AUTOSAR XML (schema 4-0-3)
package /CalibrationComponents
  parameter sw component type DHSR: data-type-mapping=DHSR_CodeDataTypeMappingsSet
    provide port DHSR_Pport: provided-interface=DHSR_if
      provided-com-specs:
        init-value=3, parameter=KeDHSR_kmh_VehSpeedProgAlwd
        init-value=0, parameter=KeDHSR_r_ChrgFactor_Val
        init-value=0, parameter=KeDHSR_r_RegenFactor_Val
        init-value=0, parameter=KeDHSR_r_SOPFactor_Val
        init-value=2, parameter=KeDHSR_t_BPOdbnc1
        init-value=5, parameter=KeDHSR_t_BPOdbnc2
        init-value=8, parameter=KeDHSR_t_BPOdbnc3
        init-value=30, parameter=KeDHSR_t_BPOdbnc4
        init-value=0, parameter=KeDHSR_b_BattPowerOff_En
        init-value=1, parameter=KeDHSR_b_BattPowerOff_Val
        init-value=0, parameter=KeDHSR_b_ChrgFactor_En
        init-value=0, parameter=KeDHSR_b_Discharge10Kw_En
        init-value=0, parameter=KeDHSR_b_Discharge10Kw_Val
        init-value=0, parameter=KeDHSR_b_FaultLamp_En
        init-value=0, parameter=KeDHSR_b_FaultLamp_Val
        init-value=0, parameter=KeDHSR_b_NoCellBalance_En
        init-value=0, parameter=KeDHSR_b_NoCellBalance_Val
        init-value=0, parameter=KeDHSR_b_NoHeat_En
        init-value=0, parameter=KeDHSR_b_NoHeat_Val
        init-value=0, parameter=KeDHSR_b_NoPrecharge_En
        init-value=0, parameter=KeDHSR_b_NoPrecharge_Val
        init-value=0, parameter=KeDHSR_b_RegenFactor_En
        init-value=0, parameter=KeDHSR_b_ReqPowerOff_En
        init-value=0, parameter=KeDHSR_b_ReqPowerOff_Val
        init-value=0, parameter=KeDHSR_b_SOCTo0_En
        init-value=0, parameter=KeDHSR_b_SOPFactor_En
        init-value=0, parameter=KeDHSR_b_SOCTo0_Val
package /DHSR_Code_pkg/DHSR_Code_swc
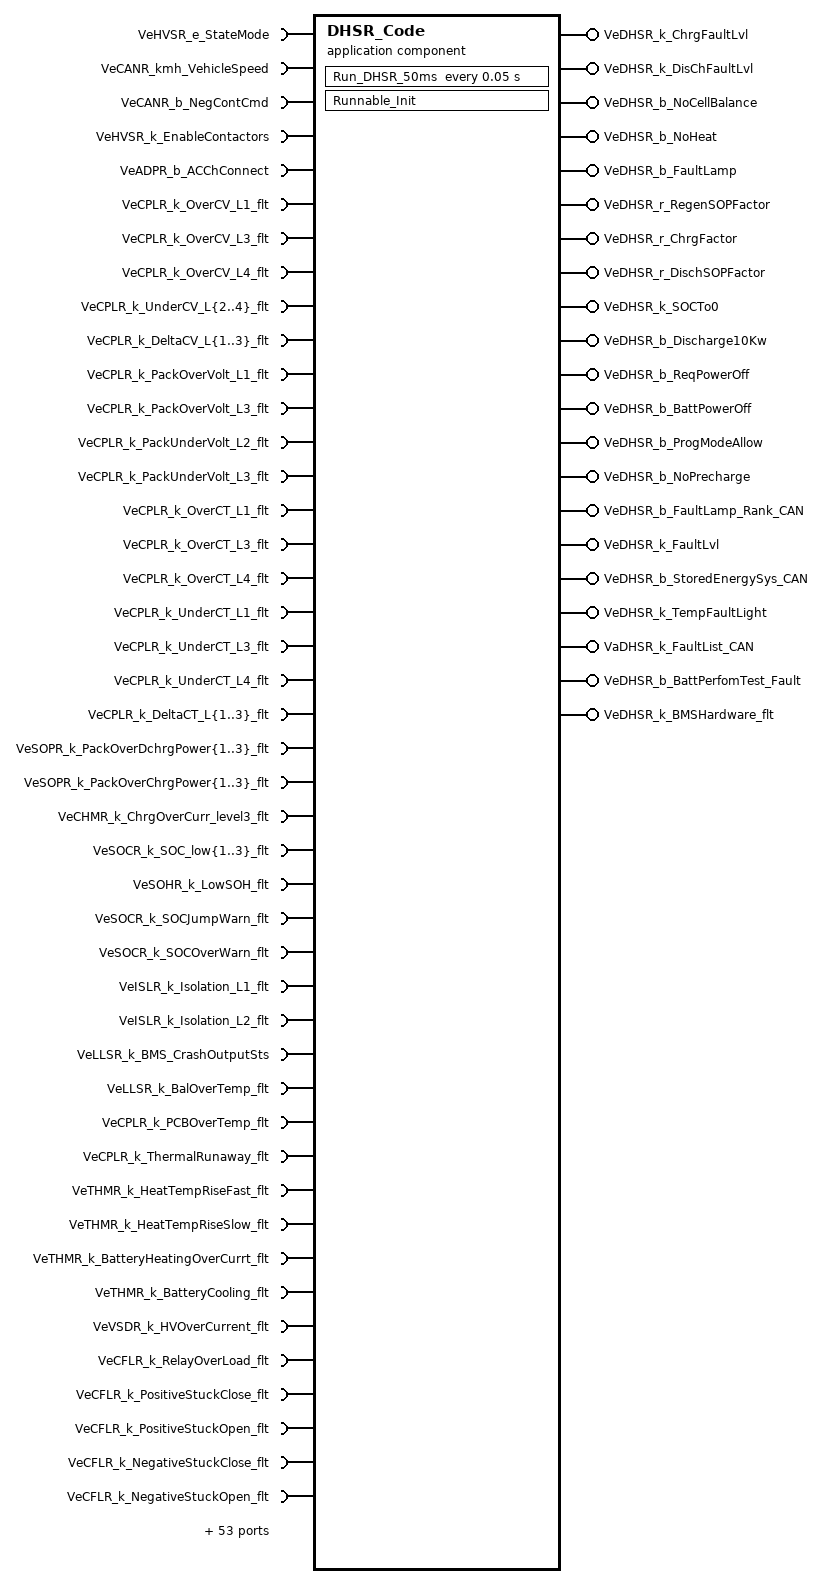
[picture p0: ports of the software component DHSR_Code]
  application sw component type DHSR_Code
    108 x require port:
      VeHVSR_e_StateMode: nonqueued-receiver-com-spec{data-element=VeHVSR_e_StateMode, init-value=CeHVSR_e_StateModeReserved}, required-interface=VeHVSR_e_StateMode
      VeCANR_kmh_VehicleSpeed: nonqueued-receiver-com-spec{data-element=VeCANR_kmh_VehicleSpeed, init-value=0}, required-interface=VeCANR_kmh_VehicleSpeed
      VeCANR_b_NegContCmd: nonqueued-receiver-com-spec{data-element=VeCANR_b_NegContCmd, init-value=0}, required-interface=VeCANR_b_NegContCmd
      VeHVSR_k_EnableContactors: nonqueued-receiver-com-spec{data-element=VeHVSR_k_EnableContactors, init-value=0}, required-interface=VeHVSR_k_EnableContactors
      VeADPR_b_ACChConnect: nonqueued-receiver-com-spec{data-element=VeADPR_b_ACChConnect, init-value=0}, required-interface=VeADPR_b_ACChConnect
      VeCPLR_k_OverCV_L1_flt: nonqueued-receiver-com-spec{data-element=VeCPLR_k_OverCV_L1_flt, init-value=0}, required-interface=VeCPLR_k_OverCV_L1_flt
      VeCPLR_k_OverCV_L3_flt: nonqueued-receiver-com-spec{data-element=VeCPLR_k_OverCV_L3_flt, init-value=0}, required-interface=VeCPLR_k_OverCV_L3_flt
      VeCPLR_k_OverCV_L4_flt: nonqueued-receiver-com-spec{data-element=VeCPLR_k_OverCV_L4_flt, init-value=0}, required-interface=VeCPLR_k_OverCV_L4_flt
      VeCPLR_k_UnderCV_L{2..4}_flt: nonqueued-receiver-com-spec{data-element=VeCPLR_k_UnderCV_L{2..4}_flt, init-value=0}, required-interface=VeCPLR_k_UnderCV_L{2..4}_flt
      VeCPLR_k_DeltaCV_L{1..3}_flt: nonqueued-receiver-com-spec{data-element=VeCPLR_k_DeltaCV_L{1..3}_flt, init-value=0}, required-interface=VeCPLR_k_DeltaCV_L{1..3}_flt
      VeCPLR_k_PackOverVolt_L1_flt: nonqueued-receiver-com-spec{data-element=VeCPLR_k_PackOverVolt_L1_flt, init-value=0}, required-interface=VeCPLR_k_PackOverVolt_L1_flt
      VeCPLR_k_PackOverVolt_L3_flt: nonqueued-receiver-com-spec{data-element=VeCPLR_k_PackOverVolt_L3_flt, init-value=0}, required-interface=VeCPLR_k_PackOverVolt_L3_flt
      VeCPLR_k_PackUnderVolt_L2_flt: nonqueued-receiver-com-spec{data-element=VeCPLR_k_PackUnderVolt_L2_flt, init-value=0}, required-interface=VeCPLR_k_PackUnderVolt_L2_flt
      VeCPLR_k_PackUnderVolt_L3_flt: nonqueued-receiver-com-spec{data-element=VeCPLR_k_PackUnderVolt_L3_flt, init-value=0}, required-interface=VeCPLR_k_PackUnderVolt_L3_flt
      VeCPLR_k_OverCT_L1_flt: nonqueued-receiver-com-spec{data-element=VeCPLR_k_OverCT_L1_flt, init-value=0}, required-interface=VeCPLR_k_OverCT_L1_flt
      VeCPLR_k_OverCT_L3_flt: nonqueued-receiver-com-spec{data-element=VeCPLR_k_OverCT_L3_flt, init-value=0}, required-interface=VeCPLR_k_OverCT_L3_flt
      VeCPLR_k_OverCT_L4_flt: nonqueued-receiver-com-spec{data-element=VeCPLR_k_OverCT_L4_flt, init-value=0}, required-interface=VeCPLR_k_OverCT_L4_flt
      VeCPLR_k_UnderCT_L1_flt: nonqueued-receiver-com-spec{data-element=VeCPLR_k_UnderCT_L1_flt, init-value=0}, required-interface=VeCPLR_k_UnderCT_L1_flt
      VeCPLR_k_UnderCT_L3_flt: nonqueued-receiver-com-spec{data-element=VeCPLR_k_UnderCT_L3_flt, init-value=0}, required-interface=VeCPLR_k_UnderCT_L3_flt
      VeCPLR_k_UnderCT_L4_flt: nonqueued-receiver-com-spec{data-element=VeCPLR_k_UnderCT_L4_flt, init-value=0}, required-interface=VeCPLR_k_UnderCT_L4_flt
      VeCPLR_k_DeltaCT_L{1..3}_flt: nonqueued-receiver-com-spec{data-element=VeCPLR_k_DeltaCT_L{1..3}_flt, init-value=0}, required-interface=VeCPLR_k_DeltaCT_L{1..3}_flt
      VeSOPR_k_PackOverDchrgPower{1..3}_flt: nonqueued-receiver-com-spec{data-element=VeSOPR_k_PackOverDchrgPower{1..3}_flt, init-value=0}, required-interface=VeSOPR_k_PackOverDchrgPower{1..3}_flt
      VeSOPR_k_PackOverChrgPower{1..3}_flt: nonqueued-receiver-com-spec{data-element=VeSOPR_k_PackOverChrgPower{1..3}_flt, init-value=0}, required-interface=VeSOPR_k_PackOverChrgPower{1..3}_flt
      VeCHMR_k_ChrgOverCurr_level3_flt: nonqueued-receiver-com-spec{data-element=VeCHMR_k_ChrgOverCurr_level3_flt, init-value=0}, required-interface=VeCHMR_k_ChrgOverCurr_level3_flt
      VeSOCR_k_SOC_low{1..3}_flt: nonqueued-receiver-com-spec{data-element=VeSOCR_k_SOC_low{1..3}_flt, init-value=0}, required-interface=VeSOCR_k_SOC_low{1..3}_flt
      VeSOHR_k_LowSOH_flt: nonqueued-receiver-com-spec{data-element=VeSOHR_k_LowSOH_flt, init-value=0}, required-interface=VeSOHR_k_LowSOH_flt
      VeSOCR_k_SOCJumpWarn_flt: nonqueued-receiver-com-spec{data-element=VeSOCR_k_SOCJumpWarn_flt, init-value=0}, required-interface=VeSOCR_k_SOCJumpWarn_flt
      VeSOCR_k_SOCOverWarn_flt: nonqueued-receiver-com-spec{data-element=VeSOCR_k_SOCOverWarn_flt, init-value=0}, required-interface=VeSOCR_k_SOCOverWarn_flt
      VeISLR_k_Isolation_L1_flt: nonqueued-receiver-com-spec{data-element=VeISLR_k_Isolation_L1_flt, init-value=0}, required-interface=VeISLR_k_Isolation_L1_flt
      VeISLR_k_Isolation_L2_flt: nonqueued-receiver-com-spec{data-element=VeISLR_k_Isolation_L2_flt, init-value=0}, required-interface=VeISLR_k_Isolation_L2_flt
      VeLLSR_k_BMS_CrashOutputSts: nonqueued-receiver-com-spec{data-element=VeLLSR_k_BMS_CrashOutputSts, init-value=0}, required-interface=VeLLSR_k_BMS_CrashOutputSts
      VeLLSR_k_BalOverTemp_flt: nonqueued-receiver-com-spec{data-element=VeLLSR_k_BalOverTemp_flt, init-value=0}, required-interface=VeLLSR_k_BalOverTemp_flt
      VeCPLR_k_PCBOverTemp_flt: nonqueued-receiver-com-spec{data-element=VeCPLR_k_PCBOverTemp_flt, init-value=0}, required-interface=VeCPLR_k_PCBOverTemp_flt
      VeCPLR_k_ThermalRunaway_flt: nonqueued-receiver-com-spec{data-element=VeCPLR_k_ThermalRunaway_flt, init-value=0}, required-interface=VeCPLR_k_ThermalRunaway_flt
      VeTHMR_k_HeatTempRiseFast_flt: nonqueued-receiver-com-spec{data-element=VeTHMR_k_HeatTempRiseFast_flt, init-value=0}, required-interface=VeTHMR_k_HeatTempRiseFast_flt
      VeTHMR_k_HeatTempRiseSlow_flt: nonqueued-receiver-com-spec{data-element=VeTHMR_k_HeatTempRiseSlow_flt, init-value=0}, required-interface=VeTHMR_k_HeatTempRiseSlow_flt
      VeTHMR_k_BatteryHeatingOverCurrt_flt: nonqueued-receiver-com-spec{data-element=VeTHMR_k_BatteryHeatingOverCurrt_flt, init-value=0}, required-interface=VeTHMR_k_BatteryHeatingOverCurrt_flt
      VeTHMR_k_BatteryCooling_flt: nonqueued-receiver-com-spec{data-element=VeTHMR_k_BatteryCooling_flt, init-value=0}, required-interface=VeTHMR_k_BatteryCooling_flt
      VeVSDR_k_HVOverCurrent_flt: nonqueued-receiver-com-spec{data-element=VeVSDR_k_HVOverCurrent_flt, init-value=0}, required-interface=VeVSDR_k_HVOverCurrent_flt
      VeCFLR_k_RelayOverLoad_flt: nonqueued-receiver-com-spec{data-element=VeCFLR_k_RelayOverLoad_flt, init-value=0}, required-interface=VeCFLR_k_RelayOverLoad_flt
      VeCFLR_k_PositiveStuckClose_flt: nonqueued-receiver-com-spec{data-element=VeCFLR_k_PositiveStuckClose_flt, init-value=0}, required-interface=VeCFLR_k_PositiveStuckClose_flt
      VeCFLR_k_PositiveStuckOpen_flt: nonqueued-receiver-com-spec{data-element=VeCFLR_k_PositiveStuckOpen_flt, init-value=0}, required-interface=VeCFLR_k_PositiveStuckOpen_flt
      VeCFLR_k_NegativeStuckClose_flt: nonqueued-receiver-com-spec{data-element=VeCFLR_k_NegativeStuckClose_flt, init-value=0}, required-interface=VeCFLR_k_NegativeStuckClose_flt
      VeCFLR_k_NegativeStuckOpen_flt: nonqueued-receiver-com-spec{data-element=VeCFLR_k_NegativeStuckOpen_flt, init-value=0}, required-interface=VeCFLR_k_NegativeStuckOpen_flt
      VeCFLR_k_PrechargeStuckClose_flt: nonqueued-receiver-com-spec{data-element=VeCFLR_k_PrechargeStuckClose_flt, init-value=0}, required-interface=VeCFLR_k_PrechargeStuckClose_flt
      VeCFLR_k_PrechargeStuckOpen_flt: nonqueued-receiver-com-spec{data-element=VeCFLR_k_PrechargeStuckOpen_flt, init-value=0}, required-interface=VeCFLR_k_PrechargeStuckOpen_flt
      VeCFLR_k_MainFuse1Open_flt: nonqueued-receiver-com-spec{data-element=VeCFLR_k_MainFuse1Open_flt, init-value=0}, required-interface=VeCFLR_k_MainFuse1Open_flt
      VeCFLR_k_MainFuse2Open_flt: nonqueued-receiver-com-spec{data-element=VeCFLR_k_MainFuse2Open_flt, init-value=0}, required-interface=VeCFLR_k_MainFuse2Open_flt
      VeHVIR_k_MainHVIL2_flt: nonqueued-receiver-com-spec{data-element=VeHVIR_k_MainHVIL2_flt, init-value=0}, required-interface=VeHVIR_k_MainHVIL2_flt
      VeHVIR_k_MainHVIL_flt: nonqueued-receiver-com-spec{data-element=VeHVIR_k_MainHVIL_flt, init-value=0}, required-interface=VeHVIR_k_MainHVIL_flt
      VeISLR_InterIsolation_flt: nonqueued-receiver-com-spec{data-element=VeISLR_InterIsolation_flt, init-value=0}, required-interface=VeISLR_InterIsolation_flt
      VeISLR_ExterIsolation_flt: nonqueued-receiver-com-spec{data-element=VeISLR_ExterIsolation_flt, init-value=0}, required-interface=VeISLR_ExterIsolation_flt
      VeCFLR_k_PreResistorStuckOpen_flt: nonqueued-receiver-com-spec{data-element=VeCFLR_k_PreResistorStuckOpen_flt, init-value=0}, required-interface=VeCFLR_k_PreResistorStuckOpen_flt
      VeCFLR_k_PreChargeFail_flt: nonqueued-receiver-com-spec{data-element=VeCFLR_k_PreChargeFail_flt, init-value=0}, required-interface=VeCFLR_k_PreChargeFail_flt
      VeCFLR_k_PreChargeOvCur_flt: nonqueued-receiver-com-spec{data-element=VeCFLR_k_PreChargeOvCur_flt, init-value=0}, required-interface=VeCFLR_k_PreChargeOvCur_flt
      VeCFLR_k_PassiveMcuDischarge_flt: nonqueued-receiver-com-spec{data-element=VeCFLR_k_PassiveMcuDischarge_flt, init-value=0}, required-interface=VeCFLR_k_PassiveMcuDischarge_flt
      VeCFLR_k_ConDrvPosCircuit_flt: nonqueued-receiver-com-spec{data-element=VeCFLR_k_ConDrvPosCircuit_flt, init-value=0}, required-interface=VeCFLR_k_ConDrvPosCircuit_flt
      VeCFLR_k_ConDrvNegCircuit_flt: nonqueued-receiver-com-spec{data-element=VeCFLR_k_ConDrvNegCircuit_flt, init-value=0}, required-interface=VeCFLR_k_ConDrvNegCircuit_flt
      VeCFLR_k_ConDrvPreCircuit_flt: nonqueued-receiver-com-spec{data-element=VeCFLR_k_ConDrvPreCircuit_flt, init-value=0}, required-interface=VeCFLR_k_ConDrvPreCircuit_flt
      VeVSDR_k_LinkVoltageInRange_flt: nonqueued-receiver-com-spec{data-element=VeVSDR_k_LinkVoltageInRange_flt, init-value=0}, required-interface=VeVSDR_k_LinkVoltageInRange_flt
      VeVSDR_k_PackVoltageInRange_flt: nonqueued-receiver-com-spec{data-element=VeVSDR_k_PackVoltageInRange_flt, init-value=0}, required-interface=VeVSDR_k_PackVoltageInRange_flt
      VeVSDR_k_VoltMCUFInRange_flt: nonqueued-receiver-com-spec{data-element=VeVSDR_k_VoltMCUFInRange_flt, init-value=0}, required-interface=VeVSDR_k_VoltMCUFInRange_flt
      VeVSDR_k_VoltMCURInRange_flt: nonqueued-receiver-com-spec{data-element=VeVSDR_k_VoltMCURInRange_flt, init-value=0}, required-interface=VeVSDR_k_VoltMCURInRange_flt
      VeCSCR_k_CellCircuit_flt: nonqueued-receiver-com-spec{data-element=VeCSCR_k_CellCircuit_flt, init-value=0}, required-interface=VeCSCR_k_CellCircuit_flt
      VeCSCR_k_StackCircuit_flt: nonqueued-receiver-com-spec{data-element=VeCSCR_k_StackCircuit_flt, init-value=0}, required-interface=VeCSCR_k_StackCircuit_flt
      VeCSCR_k_TempArray_flt: nonqueued-receiver-com-spec{data-element=VeCSCR_k_TempArray_flt, init-value=0}, required-interface=VeCSCR_k_TempArray_flt
      VeCSCR_k_PackVolt_flt: nonqueued-receiver-com-spec{data-element=VeCSCR_k_PackVolt_flt, init-value=0}, required-interface=VeCSCR_k_PackVolt_flt
      VeCSCR_k_LinkPVolt_flt: nonqueued-receiver-com-spec{data-element=VeCSCR_k_LinkPVolt_flt, init-value=0}, required-interface=VeCSCR_k_LinkPVolt_flt
      VeCSCR_k_HeatVolt_flt: nonqueued-receiver-com-spec{data-element=VeCSCR_k_HeatVolt_flt, init-value=0}, required-interface=VeCSCR_k_HeatVolt_flt
      VeCSCR_k_LinkNVolt_flt: nonqueued-receiver-com-spec{data-element=VeCSCR_k_LinkNVolt_flt, init-value=0}, required-interface=VeCSCR_k_LinkNVolt_flt
      VeLLSR_k_CrashCircuit_flt: nonqueued-receiver-com-spec{data-element=VeLLSR_k_CrashCircuit_flt, init-value=0}, required-interface=VeLLSR_k_CrashCircuit_flt
      VeLLSR_k_PackCrntCircuit_flt: nonqueued-receiver-com-spec{data-element=VeLLSR_k_PackCrntCircuit_flt, init-value=0}, required-interface=VeLLSR_k_PackCrntCircuit_flt
      VeCSCR_k_CBCircuit_flt: nonqueued-receiver-com-spec{data-element=VeCSCR_k_CBCircuit_flt, init-value=0}, required-interface=VeCSCR_k_CBCircuit_flt
      VeCSCR_k_PCBTempInv_Flt: nonqueued-receiver-com-spec{data-element=VeCSCR_k_PCBTempInv_Flt, init-value=0}, required-interface=VeCSCR_k_PCBTempInv_Flt
      VeHVIR_k_MainHVILCircuit_flt: nonqueued-receiver-com-spec{data-element=VeHVIR_k_MainHVILCircuit_flt, init-value=0}, required-interface=VeHVIR_k_MainHVILCircuit_flt
      VeHVIR_k_MainHVILCircuit2_flt: nonqueued-receiver-com-spec{data-element=VeHVIR_k_MainHVILCircuit2_flt, init-value=0}, required-interface=VeHVIR_k_MainHVILCircuit2_flt
      VeLLSR_k_ExtEEP_flt: nonqueued-receiver-com-spec{data-element=VeLLSR_k_ExtEEP_flt, init-value=0}, required-interface=VeLLSR_k_ExtEEP_flt
      VeLLSR_k_DaisyCom_flt: nonqueued-receiver-com-spec{data-element=VeLLSR_k_DaisyCom_flt, init-value=0}, required-interface=VeLLSR_k_DaisyCom_flt
      VeLLSR_k_VCUComLoss_flt: nonqueued-receiver-com-spec{data-element=VeLLSR_k_VCUComLoss_flt, init-value=0}, required-interface=VeLLSR_k_VCUComLoss_flt
      VeLLSR_k_OBCComLoss_flt: nonqueued-receiver-com-spec{data-element=VeLLSR_k_OBCComLoss_flt, init-value=0}, required-interface=VeLLSR_k_OBCComLoss_flt
      VeLLSR_k_TMFComLoss_flt: nonqueued-receiver-com-spec{data-element=VeLLSR_k_TMFComLoss_flt, init-value=0}, required-interface=VeLLSR_k_TMFComLoss_flt
      VeLLSR_k_TMRComLoss_flt: nonqueued-receiver-com-spec{data-element=VeLLSR_k_TMRComLoss_flt, init-value=0}, required-interface=VeLLSR_k_TMRComLoss_flt
      VeLLSR_k_ISGFComLoss_flt: nonqueued-receiver-com-spec{data-element=VeLLSR_k_ISGFComLoss_flt, init-value=0}, required-interface=VeLLSR_k_ISGFComLoss_flt
      VeLLSR_k_CDUComLoss_flt: nonqueued-receiver-com-spec{data-element=VeLLSR_k_CDUComLoss_flt, init-value=0}, required-interface=VeLLSR_k_CDUComLoss_flt
      VeLLSR_k_CLMComLoss_flt: nonqueued-receiver-com-spec{data-element=VeLLSR_k_CLMComLoss_flt, init-value=0}, required-interface=VeLLSR_k_CLMComLoss_flt
      VeLLSR_k_ABMComLoss_flt: nonqueued-receiver-com-spec{data-element=VeLLSR_k_ABMComLoss_flt, init-value=0}, required-interface=VeLLSR_k_ABMComLoss_flt
      VeLLSR_k_ICMComLoss_flt: nonqueued-receiver-com-spec{data-element=VeLLSR_k_ICMComLoss_flt, init-value=0}, required-interface=VeLLSR_k_ICMComLoss_flt
      VeLLSR_k_TBOXComLoss_flt: nonqueued-receiver-com-spec{data-element=VeLLSR_k_TBOXComLoss_flt, init-value=0}, required-interface=VeLLSR_k_TBOXComLoss_flt
      VeLLSR_k_BSMComLoss_flt: nonqueued-receiver-com-spec{data-element=VeLLSR_k_BSMComLoss_flt, init-value=0}, required-interface=VeLLSR_k_BSMComLoss_flt
      VeLLSR_k_EMSComLoss_flt: nonqueued-receiver-com-spec{data-element=VeLLSR_k_EMSComLoss_flt, init-value=0}, required-interface=VeLLSR_k_EMSComLoss_flt
      VeLLSR_k_VehCANBusOff_flt: nonqueued-receiver-com-spec{data-element=VeLLSR_k_VehCANBusOff_flt, init-value=0}, required-interface=VeLLSR_k_VehCANBusOff_flt
      VeLLSR_k_KL30UnderVoltage_flt: nonqueued-receiver-com-spec{data-element=VeLLSR_k_KL30UnderVoltage_flt, init-value=0}, required-interface=VeLLSR_k_KL30UnderVoltage_flt
      VeLLSR_k_KL30OverVoltage_flt: nonqueued-receiver-com-spec{data-element=VeLLSR_k_KL30OverVoltage_flt, init-value=0}, required-interface=VeLLSR_k_KL30OverVoltage_flt
      VeLLSR_k_KL30AccidentalPowerOff_flt: nonqueued-receiver-com-spec{data-element=VeLLSR_k_KL30AccidentalPowerOff_flt, init-value=0}, required-interface=VeLLSR_k_KL30AccidentalPowerOff_flt
      VeCFLR_k_UnexpectedContOpen_flt: nonqueued-receiver-com-spec{data-element=VeCFLR_k_UnexpectedContOpen_flt, init-value=0}, required-interface=VeCFLR_k_UnexpectedContOpen_flt
      VeLLSR_k_AbnormalShutdownDetected: nonqueued-receiver-com-spec{data-element=VeLLSR_k_AbnormalShutdownDetected, init-value=0}, required-interface=VeLLSR_k_AbnormalShutdownDetected
    21 x provide port:
      VeDHSR_k_ChrgFaultLvl: nonqueued-sender-com-spec{data-element=VeDHSR_k_ChrgFaultLvl, init-value=0}, provided-interface=VeDHSR_k_ChrgFaultLvl
      VeDHSR_k_DisChFaultLvl: nonqueued-sender-com-spec{data-element=VeDHSR_k_DisChFaultLvl, init-value=0}, provided-interface=VeDHSR_k_DisChFaultLvl
      VeDHSR_b_NoCellBalance: nonqueued-sender-com-spec{data-element=VeDHSR_b_NoCellBalance, init-value=0}, provided-interface=VeDHSR_b_NoCellBalance
      VeDHSR_b_NoHeat: nonqueued-sender-com-spec{data-element=VeDHSR_b_NoHeat, init-value=0}, provided-interface=VeDHSR_b_NoHeat
      VeDHSR_b_FaultLamp: nonqueued-sender-com-spec{data-element=VeDHSR_b_FaultLamp, init-value=0}, provided-interface=VeDHSR_b_FaultLamp
      VeDHSR_r_RegenSOPFactor: nonqueued-sender-com-spec{data-element=VeDHSR_r_RegenSOPFactor, init-value=0}, provided-interface=VeDHSR_r_RegenSOPFactor
      VeDHSR_r_ChrgFactor: nonqueued-sender-com-spec{data-element=VeDHSR_r_ChrgFactor, init-value=0}, provided-interface=VeDHSR_r_ChrgFactor
      VeDHSR_r_DischSOPFactor: nonqueued-sender-com-spec{data-element=VeDHSR_r_DischSOPFactor, init-value=0}, provided-interface=VeDHSR_r_DischSOPFactor
      VeDHSR_k_SOCTo0: nonqueued-sender-com-spec{data-element=VeDHSR_k_SOCTo0, init-value=0}, provided-interface=VeDHSR_k_SOCTo0
      VeDHSR_b_Discharge10Kw: nonqueued-sender-com-spec{data-element=VeDHSR_b_Discharge10Kw, init-value=0}, provided-interface=VeDHSR_b_Discharge10Kw
      VeDHSR_b_ReqPowerOff: nonqueued-sender-com-spec{data-element=VeDHSR_b_ReqPowerOff, init-value=0}, provided-interface=VeDHSR_b_ReqPowerOff
      VeDHSR_b_BattPowerOff: nonqueued-sender-com-spec{data-element=VeDHSR_b_BattPowerOff, init-value=0}, provided-interface=VeDHSR_b_BattPowerOff
      VeDHSR_b_ProgModeAllow: nonqueued-sender-com-spec{data-element=VeDHSR_b_ProgModeAllow, init-value=0}, provided-interface=VeDHSR_b_ProgModeAllow
      VeDHSR_b_NoPrecharge: nonqueued-sender-com-spec{data-element=VeDHSR_b_NoPrecharge, init-value=0}, provided-interface=VeDHSR_b_NoPrecharge
      VeDHSR_b_FaultLamp_Rank_CAN: nonqueued-sender-com-spec{data-element=VeDHSR_b_FaultLamp_Rank_CAN, init-value=0}, provided-interface=VeDHSR_b_FaultLamp_Rank_CAN
      VeDHSR_k_FaultLvl: nonqueued-sender-com-spec{data-element=VeDHSR_k_FaultLvl, init-value=0}, provided-interface=VeDHSR_k_FaultLvl
      VeDHSR_b_StoredEnergySys_CAN: nonqueued-sender-com-spec{data-element=VeDHSR_b_StoredEnergySys_CAN, init-value=0}, provided-interface=VeDHSR_b_StoredEnergySys_CAN
      VeDHSR_k_TempFaultLight: nonqueued-sender-com-spec{data-element=VeDHSR_k_TempFaultLight, init-value=0}, provided-interface=VeDHSR_k_TempFaultLight
      VaDHSR_k_FaultList_CAN: nonqueued-sender-com-spec{data-element=VaDHSR_k_FaultList_CAN, init-value=15 x 0}, provided-interface=VaDHSR_k_FaultList_CAN
      VeDHSR_b_BattPerfomTest_Fault: nonqueued-sender-com-spec{data-element=VeDHSR_b_BattPerfomTest_Fault, init-value=0}, provided-interface=VeDHSR_b_BattPerfomTest_Fault
      VeDHSR_k_BMSHardware_flt: nonqueued-sender-com-spec{data-element=VeDHSR_k_BMSHardware_flt, init-value=0}, provided-interface=VeDHSR_k_BMSHardware_flt
    require port DHSR_Rport: required-interface=DHSR_if
    behavior DHSR_Code: data-type-mapping=DHSR_CodeDataTypeMappingsSet, handle-termination-and-restart=NO-SUPPORT
      constant-memorys:
        5 x parameter data prototype, all with category=ARRAY, sw-calibration-access=READ-WRITE:
          CzDHSR_K_FaultMatrixAC: type=rt_Array_Boolean_2080, init-value=constant-reference={short-label=CzDHSR_K_FaultMatrixAC, constant=CzDHSR_K_FaultMatrixAC}
          CzDHSR_K_FaultMatrixDC: type=rt_Array_Boolean_2080, init-value=constant-reference={short-label=CzDHSR_K_FaultMatrixDC, constant=CzDHSR_K_FaultMatrixDC}
          CzDHSR_K_FaultMatrixOP: type=rt_Array_Boolean_2080, init-value=constant-reference={short-label=CzDHSR_K_FaultMatrixOP, constant=CzDHSR_K_FaultMatrixOP}
          CzDHSR_k_ChargeFaultLevel: type=rt_Array_UInt8_104, init-value=constant-reference={short-label=CzDHSR_k_ChargeFaultLevel, constant=CzDHSR_k_ChargeFaultLevel}
          CzDHSR_k_DischargeFaultLevel: type=rt_Array_UInt8_104, init-value=constant-reference={short-label=CzDHSR_k_DischargeFaultLevel, constant=CzDHSR_k_DischargeFaultLevel}
      timing event Event_Run_DHSR_50ms: start-on-event=Run_DHSR_50ms, period=0.05
      runnable Runnable_Init: symbol=DHSR_Code_Init
        data-send-points:
          access OUT_VeDHSR_b_ProgModeAllow_VeDHSR_b_ProgModeAllow: accessed-variable=VeDHSR_b_ProgModeAllow.VeDHSR_b_ProgModeAllow
      runnable Run_DHSR_50ms
        data-read-access:
          108 x access:
            IN_VeADPR_b_ACChConnect_VeADPR_b_ACChConnect: accessed-variable=VeADPR_b_ACChConnect.VeADPR_b_ACChConnect
            IN_VeCANR_b_NegContCmd_VeCANR_b_NegContCmd: accessed-variable=VeCANR_b_NegContCmd.VeCANR_b_NegContCmd
            IN_VeCANR_kmh_VehicleSpeed_VeCANR_kmh_VehicleSpeed: accessed-variable=VeCANR_kmh_VehicleSpeed.VeCANR_kmh_VehicleSpeed
            IN_VeCFLR_k_ConDrvNegCircuit_flt_VeCFLR_k_ConDrvNegCircuit_flt: accessed-variable=VeCFLR_k_ConDrvNegCircuit_flt.VeCFLR_k_ConDrvNegCircuit_flt
            IN_VeCFLR_k_ConDrvPosCircuit_flt_VeCFLR_k_ConDrvPosCircuit_flt: accessed-variable=VeCFLR_k_ConDrvPosCircuit_flt.VeCFLR_k_ConDrvPosCircuit_flt
            IN_VeCFLR_k_ConDrvPreCircuit_flt_VeCFLR_k_ConDrvPreCircuit_flt: accessed-variable=VeCFLR_k_ConDrvPreCircuit_flt.VeCFLR_k_ConDrvPreCircuit_flt
            IN_VeCFLR_k_MainFuse1Open_flt_VeCFLR_k_MainFuse1Open_flt: accessed-variable=VeCFLR_k_MainFuse1Open_flt.VeCFLR_k_MainFuse1Open_flt
            IN_VeCFLR_k_MainFuse2Open_flt_VeCFLR_k_MainFuse2Open_flt: accessed-variable=VeCFLR_k_MainFuse2Open_flt.VeCFLR_k_MainFuse2Open_flt
            IN_VeCFLR_k_NegativeStuckClose_flt_VeCFLR_k_N_d34448eca8e680af: accessed-variable=VeCFLR_k_NegativeStuckClose_flt.VeCFLR_k_NegativeStuckClose_flt
            IN_VeCFLR_k_NegativeStuckOpen_flt_VeCFLR_k_Ne_d0f8eb74df06d49e: accessed-variable=VeCFLR_k_NegativeStuckOpen_flt.VeCFLR_k_NegativeStuckOpen_flt
            IN_VeCFLR_k_PassiveMcuDischarge_flt_VeCFLR_k_6b19c5ef12bb9a3c: accessed-variable=VeCFLR_k_PassiveMcuDischarge_flt.VeCFLR_k_PassiveMcuDischarge_flt
            IN_VeCFLR_k_PositiveStuckClose_flt_VeCFLR_k_P_252f9e9e2c90b159: accessed-variable=VeCFLR_k_PositiveStuckClose_flt.VeCFLR_k_PositiveStuckClose_flt
            IN_VeCFLR_k_PositiveStuckOpen_flt_VeCFLR_k_Po_a050a98c9400777f: accessed-variable=VeCFLR_k_PositiveStuckOpen_flt.VeCFLR_k_PositiveStuckOpen_flt
            IN_VeCFLR_k_PreChargeFail_flt_VeCFLR_k_PreChargeFail_flt: accessed-variable=VeCFLR_k_PreChargeFail_flt.VeCFLR_k_PreChargeFail_flt
            IN_VeCFLR_k_PreChargeOvCur_flt_VeCFLR_k_PreChargeOvCur_flt: accessed-variable=VeCFLR_k_PreChargeOvCur_flt.VeCFLR_k_PreChargeOvCur_flt
            IN_VeCFLR_k_PreResistorStuckOpen_flt_VeCFLR_k_7a78a2e6a2c4c04e: accessed-variable=VeCFLR_k_PreResistorStuckOpen_flt.VeCFLR_k_PreResistorStuckOpen_flt
            IN_VeCFLR_k_PrechargeStuckClose_flt_VeCFLR_k_948f5890de14fe6e: accessed-variable=VeCFLR_k_PrechargeStuckClose_flt.VeCFLR_k_PrechargeStuckClose_flt
            IN_VeCFLR_k_PrechargeStuckOpen_flt_VeCFLR_k_P_f168f7f305ca8894: accessed-variable=VeCFLR_k_PrechargeStuckOpen_flt.VeCFLR_k_PrechargeStuckOpen_flt
            IN_VeCFLR_k_RelayOverLoad_flt_VeCFLR_k_RelayOverLoad_flt: accessed-variable=VeCFLR_k_RelayOverLoad_flt.VeCFLR_k_RelayOverLoad_flt
            IN_VeCFLR_k_UnexpectedContOpen_flt_VeCFLR_k_U_e051487bd0602cd8: accessed-variable=VeCFLR_k_UnexpectedContOpen_flt.VeCFLR_k_UnexpectedContOpen_flt
            IN_VeCHMR_k_ChrgOverCurr_level3_flt_VeCHMR_k_cb6cb1babaf3e238: accessed-variable=VeCHMR_k_ChrgOverCurr_level3_flt.VeCHMR_k_ChrgOverCurr_level3_flt
            IN_VeCPLR_k_DeltaCT_L{1..3}_flt_VeCPLR_k_DeltaCT_L{1..3}_flt: accessed-variable=VeCPLR_k_DeltaCT_L{1..3}_flt.VeCPLR_k_DeltaCT_L{1..3}_flt
            IN_VeCPLR_k_DeltaCV_L{1..3}_flt_VeCPLR_k_DeltaCV_L{1..3}_flt: accessed-variable=VeCPLR_k_DeltaCV_L{1..3}_flt.VeCPLR_k_DeltaCV_L{1..3}_flt
            IN_VeCPLR_k_OverCT_L1_flt_VeCPLR_k_OverCT_L1_flt: accessed-variable=VeCPLR_k_OverCT_L1_flt.VeCPLR_k_OverCT_L1_flt
            IN_VeCPLR_k_OverCT_L3_flt_VeCPLR_k_OverCT_L3_flt: accessed-variable=VeCPLR_k_OverCT_L3_flt.VeCPLR_k_OverCT_L3_flt
            IN_VeCPLR_k_OverCT_L4_flt_VeCPLR_k_OverCT_L4_flt: accessed-variable=VeCPLR_k_OverCT_L4_flt.VeCPLR_k_OverCT_L4_flt
            IN_VeCPLR_k_OverCV_L1_flt_VeCPLR_k_OverCV_L1_flt: accessed-variable=VeCPLR_k_OverCV_L1_flt.VeCPLR_k_OverCV_L1_flt
            IN_VeCPLR_k_OverCV_L3_flt_VeCPLR_k_OverCV_L3_flt: accessed-variable=VeCPLR_k_OverCV_L3_flt.VeCPLR_k_OverCV_L3_flt
            IN_VeCPLR_k_OverCV_L4_flt_VeCPLR_k_OverCV_L4_flt: accessed-variable=VeCPLR_k_OverCV_L4_flt.VeCPLR_k_OverCV_L4_flt
            IN_VeCPLR_k_PCBOverTemp_flt_VeCPLR_k_PCBOverTemp_flt: accessed-variable=VeCPLR_k_PCBOverTemp_flt.VeCPLR_k_PCBOverTemp_flt
            IN_VeCPLR_k_PackOverVolt_L1_flt_VeCPLR_k_PackOverVolt_L1_flt: accessed-variable=VeCPLR_k_PackOverVolt_L1_flt.VeCPLR_k_PackOverVolt_L1_flt
            IN_VeCPLR_k_PackOverVolt_L3_flt_VeCPLR_k_PackOverVolt_L3_flt: accessed-variable=VeCPLR_k_PackOverVolt_L3_flt.VeCPLR_k_PackOverVolt_L3_flt
            IN_VeCPLR_k_PackUnderVolt_L2_flt_VeCPLR_k_PackUnderVolt_L2_flt: accessed-variable=VeCPLR_k_PackUnderVolt_L2_flt.VeCPLR_k_PackUnderVolt_L2_flt
            IN_VeCPLR_k_PackUnderVolt_L3_flt_VeCPLR_k_PackUnderVolt_L3_flt: accessed-variable=VeCPLR_k_PackUnderVolt_L3_flt.VeCPLR_k_PackUnderVolt_L3_flt
            IN_VeCPLR_k_ThermalRunaway_flt_VeCPLR_k_ThermalRunaway_flt: accessed-variable=VeCPLR_k_ThermalRunaway_flt.VeCPLR_k_ThermalRunaway_flt
            IN_VeCPLR_k_UnderCT_L1_flt_VeCPLR_k_UnderCT_L1_flt: accessed-variable=VeCPLR_k_UnderCT_L1_flt.VeCPLR_k_UnderCT_L1_flt
            IN_VeCPLR_k_UnderCT_L3_flt_VeCPLR_k_UnderCT_L3_flt: accessed-variable=VeCPLR_k_UnderCT_L3_flt.VeCPLR_k_UnderCT_L3_flt
            IN_VeCPLR_k_UnderCT_L4_flt_VeCPLR_k_UnderCT_L4_flt: accessed-variable=VeCPLR_k_UnderCT_L4_flt.VeCPLR_k_UnderCT_L4_flt
            IN_VeCPLR_k_UnderCV_L{2..4}_flt_VeCPLR_k_UnderCV_L{2..4}_flt: accessed-variable=VeCPLR_k_UnderCV_L{2..4}_flt.VeCPLR_k_UnderCV_L{2..4}_flt
            IN_VeCSCR_k_CBCircuit_flt_VeCSCR_k_CBCircuit_flt: accessed-variable=VeCSCR_k_CBCircuit_flt.VeCSCR_k_CBCircuit_flt
            IN_VeCSCR_k_CellCircuit_flt_VeCSCR_k_CellCircuit_flt: accessed-variable=VeCSCR_k_CellCircuit_flt.VeCSCR_k_CellCircuit_flt
            IN_VeCSCR_k_HeatVolt_flt_VeCSCR_k_HeatVolt_flt: accessed-variable=VeCSCR_k_HeatVolt_flt.VeCSCR_k_HeatVolt_flt
            IN_VeCSCR_k_LinkNVolt_flt_VeCSCR_k_LinkNVolt_flt: accessed-variable=VeCSCR_k_LinkNVolt_flt.VeCSCR_k_LinkNVolt_flt
            IN_VeCSCR_k_LinkPVolt_flt_VeCSCR_k_LinkPVolt_flt: accessed-variable=VeCSCR_k_LinkPVolt_flt.VeCSCR_k_LinkPVolt_flt
            IN_VeCSCR_k_PCBTempInv_Flt_VeCSCR_k_PCBTempInv_Flt: accessed-variable=VeCSCR_k_PCBTempInv_Flt.VeCSCR_k_PCBTempInv_Flt
            IN_VeCSCR_k_PackVolt_flt_VeCSCR_k_PackVolt_flt: accessed-variable=VeCSCR_k_PackVolt_flt.VeCSCR_k_PackVolt_flt
            IN_VeCSCR_k_StackCircuit_flt_VeCSCR_k_StackCircuit_flt: accessed-variable=VeCSCR_k_StackCircuit_flt.VeCSCR_k_StackCircuit_flt
            IN_VeCSCR_k_TempArray_flt_VeCSCR_k_TempArray_flt: accessed-variable=VeCSCR_k_TempArray_flt.VeCSCR_k_TempArray_flt
            IN_VeHVIR_k_MainHVIL2_flt_VeHVIR_k_MainHVIL2_flt: accessed-variable=VeHVIR_k_MainHVIL2_flt.VeHVIR_k_MainHVIL2_flt
            IN_VeHVIR_k_MainHVILCircuit2_flt_VeHVIR_k_MainHVILCircuit2_flt: accessed-variable=VeHVIR_k_MainHVILCircuit2_flt.VeHVIR_k_MainHVILCircuit2_flt
            IN_VeHVIR_k_MainHVILCircuit_flt_VeHVIR_k_MainHVILCircuit_flt: accessed-variable=VeHVIR_k_MainHVILCircuit_flt.VeHVIR_k_MainHVILCircuit_flt
            IN_VeHVIR_k_MainHVIL_flt_VeHVIR_k_MainHVIL_flt: accessed-variable=VeHVIR_k_MainHVIL_flt.VeHVIR_k_MainHVIL_flt
            IN_VeHVSR_e_StateMode_VeHVSR_e_StateMode: accessed-variable=VeHVSR_e_StateMode.VeHVSR_e_StateMode
            IN_VeHVSR_k_EnableContactors_VeHVSR_k_EnableContactors: accessed-variable=VeHVSR_k_EnableContactors.VeHVSR_k_EnableContactors
            IN_VeISLR_ExterIsolation_flt_VeISLR_ExterIsolation_flt: accessed-variable=VeISLR_ExterIsolation_flt.VeISLR_ExterIsolation_flt
            IN_VeISLR_InterIsolation_flt_VeISLR_InterIsolation_flt: accessed-variable=VeISLR_InterIsolation_flt.VeISLR_InterIsolation_flt
            IN_VeISLR_k_Isolation_L1_flt_VeISLR_k_Isolation_L1_flt: accessed-variable=VeISLR_k_Isolation_L1_flt.VeISLR_k_Isolation_L1_flt
            IN_VeISLR_k_Isolation_L2_flt_VeISLR_k_Isolation_L2_flt: accessed-variable=VeISLR_k_Isolation_L2_flt.VeISLR_k_Isolation_L2_flt
            IN_VeLLSR_k_ABMComLoss_flt_VeLLSR_k_ABMComLoss_flt: accessed-variable=VeLLSR_k_ABMComLoss_flt.VeLLSR_k_ABMComLoss_flt
            IN_VeLLSR_k_AbnormalShutdownDetected_VeLLSR_k_ec2914bc9e11adf9: accessed-variable=VeLLSR_k_AbnormalShutdownDetected.VeLLSR_k_AbnormalShutdownDetected
            IN_VeLLSR_k_BMS_CrashOutputSts_VeLLSR_k_BMS_CrashOutputSts: accessed-variable=VeLLSR_k_BMS_CrashOutputSts.VeLLSR_k_BMS_CrashOutputSts
            IN_VeLLSR_k_BSMComLoss_flt_VeLLSR_k_BSMComLoss_flt: accessed-variable=VeLLSR_k_BSMComLoss_flt.VeLLSR_k_BSMComLoss_flt
            IN_VeLLSR_k_BalOverTemp_flt_VeLLSR_k_BalOverTemp_flt: accessed-variable=VeLLSR_k_BalOverTemp_flt.VeLLSR_k_BalOverTemp_flt
            IN_VeLLSR_k_CDUComLoss_flt_VeLLSR_k_CDUComLoss_flt: accessed-variable=VeLLSR_k_CDUComLoss_flt.VeLLSR_k_CDUComLoss_flt
            IN_VeLLSR_k_CLMComLoss_flt_VeLLSR_k_CLMComLoss_flt: accessed-variable=VeLLSR_k_CLMComLoss_flt.VeLLSR_k_CLMComLoss_flt
            IN_VeLLSR_k_CrashCircuit_flt_VeLLSR_k_CrashCircuit_flt: accessed-variable=VeLLSR_k_CrashCircuit_flt.VeLLSR_k_CrashCircuit_flt
            IN_VeLLSR_k_DaisyCom_flt_VeLLSR_k_DaisyCom_flt: accessed-variable=VeLLSR_k_DaisyCom_flt.VeLLSR_k_DaisyCom_flt
            IN_VeLLSR_k_EMSComLoss_flt_VeLLSR_k_EMSComLoss_flt: accessed-variable=VeLLSR_k_EMSComLoss_flt.VeLLSR_k_EMSComLoss_flt
            IN_VeLLSR_k_ExtEEP_flt_VeLLSR_k_ExtEEP_flt: accessed-variable=VeLLSR_k_ExtEEP_flt.VeLLSR_k_ExtEEP_flt
            IN_VeLLSR_k_ICMComLoss_flt_VeLLSR_k_ICMComLoss_flt: accessed-variable=VeLLSR_k_ICMComLoss_flt.VeLLSR_k_ICMComLoss_flt
            IN_VeLLSR_k_ISGFComLoss_flt_VeLLSR_k_ISGFComLoss_flt: accessed-variable=VeLLSR_k_ISGFComLoss_flt.VeLLSR_k_ISGFComLoss_flt
            IN_VeLLSR_k_KL30AccidentalPowerOff_flt_VeLLSR_3e8e47e27a63d343: accessed-variable=VeLLSR_k_KL30AccidentalPowerOff_flt.VeLLSR_k_KL30AccidentalPowerOff_flt
            IN_VeLLSR_k_KL30OverVoltage_flt_VeLLSR_k_KL30OverVoltage_flt: accessed-variable=VeLLSR_k_KL30OverVoltage_flt.VeLLSR_k_KL30OverVoltage_flt
            IN_VeLLSR_k_KL30UnderVoltage_flt_VeLLSR_k_KL30UnderVoltage_flt: accessed-variable=VeLLSR_k_KL30UnderVoltage_flt.VeLLSR_k_KL30UnderVoltage_flt
            IN_VeLLSR_k_OBCComLoss_flt_VeLLSR_k_OBCComLoss_flt: accessed-variable=VeLLSR_k_OBCComLoss_flt.VeLLSR_k_OBCComLoss_flt
            IN_VeLLSR_k_PackCrntCircuit_flt_VeLLSR_k_PackCrntCircuit_flt: accessed-variable=VeLLSR_k_PackCrntCircuit_flt.VeLLSR_k_PackCrntCircuit_flt
            IN_VeLLSR_k_TBOXComLoss_flt_VeLLSR_k_TBOXComLoss_flt: accessed-variable=VeLLSR_k_TBOXComLoss_flt.VeLLSR_k_TBOXComLoss_flt
            IN_VeLLSR_k_TMFComLoss_flt_VeLLSR_k_TMFComLoss_flt: accessed-variable=VeLLSR_k_TMFComLoss_flt.VeLLSR_k_TMFComLoss_flt
            IN_VeLLSR_k_TMRComLoss_flt_VeLLSR_k_TMRComLoss_flt: accessed-variable=VeLLSR_k_TMRComLoss_flt.VeLLSR_k_TMRComLoss_flt
            IN_VeLLSR_k_VCUComLoss_flt_VeLLSR_k_VCUComLoss_flt: accessed-variable=VeLLSR_k_VCUComLoss_flt.VeLLSR_k_VCUComLoss_flt
            IN_VeLLSR_k_VehCANBusOff_flt_VeLLSR_k_VehCANBusOff_flt: accessed-variable=VeLLSR_k_VehCANBusOff_flt.VeLLSR_k_VehCANBusOff_flt
            IN_VeSOCR_k_SOCJumpWarn_flt_VeSOCR_k_SOCJumpWarn_flt: accessed-variable=VeSOCR_k_SOCJumpWarn_flt.VeSOCR_k_SOCJumpWarn_flt
            IN_VeSOCR_k_SOCOverWarn_flt_VeSOCR_k_SOCOverWarn_flt: accessed-variable=VeSOCR_k_SOCOverWarn_flt.VeSOCR_k_SOCOverWarn_flt
            IN_VeSOCR_k_SOC_low{1..3}_flt_VeSOCR_k_SOC_low{1..3}_flt: accessed-variable=VeSOCR_k_SOC_low{1..3}_flt.VeSOCR_k_SOC_low{1..3}_flt
            IN_VeSOHR_k_LowSOH_flt_VeSOHR_k_LowSOH_flt: accessed-variable=VeSOHR_k_LowSOH_flt.VeSOHR_k_LowSOH_flt
            IN_VeSOPR_k_PackOverChrgPower1_flt_VeSOPR_k_P_45bfa2079dcf22d0: accessed-variable=VeSOPR_k_PackOverChrgPower1_flt.VeSOPR_k_PackOverChrgPower1_flt
            IN_VeSOPR_k_PackOverChrgPower2_flt_VeSOPR_k_P_48fcb83d9a1ab277: accessed-variable=VeSOPR_k_PackOverChrgPower2_flt.VeSOPR_k_PackOverChrgPower2_flt
            IN_VeSOPR_k_PackOverChrgPower3_flt_VeSOPR_k_P_8717c3fba32c28c9: accessed-variable=VeSOPR_k_PackOverChrgPower3_flt.VeSOPR_k_PackOverChrgPower3_flt
            IN_VeSOPR_k_PackOverDchrgPower1_flt_VeSOPR_k_98e3630adf80b922: accessed-variable=VeSOPR_k_PackOverDchrgPower1_flt.VeSOPR_k_PackOverDchrgPower1_flt
            IN_VeSOPR_k_PackOverDchrgPower2_flt_VeSOPR_k_853e3c41b7056cf3: accessed-variable=VeSOPR_k_PackOverDchrgPower2_flt.VeSOPR_k_PackOverDchrgPower2_flt
            IN_VeSOPR_k_PackOverDchrgPower3_flt_VeSOPR_k_9db38f702a7952fe: accessed-variable=VeSOPR_k_PackOverDchrgPower3_flt.VeSOPR_k_PackOverDchrgPower3_flt
            IN_VeTHMR_k_BatteryCooling_flt_VeTHMR_k_BatteryCooling_flt: accessed-variable=VeTHMR_k_BatteryCooling_flt.VeTHMR_k_BatteryCooling_flt
            IN_VeTHMR_k_BatteryHeatingOverCurrt_flt_VeTHM_e642e98651566152: accessed-variable=VeTHMR_k_BatteryHeatingOverCurrt_flt.VeTHMR_k_BatteryHeatingOverCurrt_flt
            IN_VeTHMR_k_HeatTempRiseFast_flt_VeTHMR_k_HeatTempRiseFast_flt: accessed-variable=VeTHMR_k_HeatTempRiseFast_flt.VeTHMR_k_HeatTempRiseFast_flt
            IN_VeTHMR_k_HeatTempRiseSlow_flt_VeTHMR_k_HeatTempRiseSlow_flt: accessed-variable=VeTHMR_k_HeatTempRiseSlow_flt.VeTHMR_k_HeatTempRiseSlow_flt
            IN_VeVSDR_k_HVOverCurrent_flt_VeVSDR_k_HVOverCurrent_flt: accessed-variable=VeVSDR_k_HVOverCurrent_flt.VeVSDR_k_HVOverCurrent_flt
            IN_VeVSDR_k_LinkVoltageInRange_flt_VeVSDR_k_L_e79c062f163f32ce: accessed-variable=VeVSDR_k_LinkVoltageInRange_flt.VeVSDR_k_LinkVoltageInRange_flt
            IN_VeVSDR_k_PackVoltageInRange_flt_VeVSDR_k_P_7e1e22cf75f7164c: accessed-variable=VeVSDR_k_PackVoltageInRange_flt.VeVSDR_k_PackVoltageInRange_flt
            IN_VeVSDR_k_VoltMCUFInRange_flt_VeVSDR_k_VoltMCUFInRange_flt: accessed-variable=VeVSDR_k_VoltMCUFInRange_flt.VeVSDR_k_VoltMCUFInRange_flt
            IN_VeVSDR_k_VoltMCURInRange_flt_VeVSDR_k_VoltMCURInRange_flt: accessed-variable=VeVSDR_k_VoltMCURInRange_flt.VeVSDR_k_VoltMCURInRange_flt
        data-send-points:
          21 x access:
            OUT_VeDHSR_k_ChrgFaultLvl_VeDHSR_k_ChrgFaultLvl: accessed-variable=VeDHSR_k_ChrgFaultLvl.VeDHSR_k_ChrgFaultLvl
            OUT_VeDHSR_k_DisChFaultLvl_VeDHSR_k_DisChFaultLvl: accessed-variable=VeDHSR_k_DisChFaultLvl.VeDHSR_k_DisChFaultLvl
            OUT_VeDHSR_b_NoCellBalance_VeDHSR_b_NoCellBalance: accessed-variable=VeDHSR_b_NoCellBalance.VeDHSR_b_NoCellBalance
            OUT_VeDHSR_b_NoHeat_VeDHSR_b_NoHeat: accessed-variable=VeDHSR_b_NoHeat.VeDHSR_b_NoHeat
            OUT_VeDHSR_b_FaultLamp_VeDHSR_b_FaultLamp: accessed-variable=VeDHSR_b_FaultLamp.VeDHSR_b_FaultLamp
            OUT_VeDHSR_r_RegenSOPFactor_VeDHSR_r_RegenSOPFactor: accessed-variable=VeDHSR_r_RegenSOPFactor.VeDHSR_r_RegenSOPFactor
            OUT_VeDHSR_r_ChrgFactor_VeDHSR_r_ChrgFactor: accessed-variable=VeDHSR_r_ChrgFactor.VeDHSR_r_ChrgFactor
            OUT_VeDHSR_r_DischSOPFactor_VeDHSR_r_DischSOPFactor: accessed-variable=VeDHSR_r_DischSOPFactor.VeDHSR_r_DischSOPFactor
            OUT_VeDHSR_k_SOCTo0_VeDHSR_k_SOCTo0: accessed-variable=VeDHSR_k_SOCTo0.VeDHSR_k_SOCTo0
            OUT_VeDHSR_b_Discharge10Kw_VeDHSR_b_Discharge10Kw: accessed-variable=VeDHSR_b_Discharge10Kw.VeDHSR_b_Discharge10Kw
            OUT_VeDHSR_b_ReqPowerOff_VeDHSR_b_ReqPowerOff: accessed-variable=VeDHSR_b_ReqPowerOff.VeDHSR_b_ReqPowerOff
            OUT_VeDHSR_b_BattPowerOff_VeDHSR_b_BattPowerOff: accessed-variable=VeDHSR_b_BattPowerOff.VeDHSR_b_BattPowerOff
            OUT_VeDHSR_b_ProgModeAllow_VeDHSR_b_ProgModeAllow: accessed-variable=VeDHSR_b_ProgModeAllow.VeDHSR_b_ProgModeAllow
            OUT_VeDHSR_b_NoPrecharge_VeDHSR_b_NoPrecharge: accessed-variable=VeDHSR_b_NoPrecharge.VeDHSR_b_NoPrecharge
            OUT_VeDHSR_k_FaultLvl_VeDHSR_k_FaultLvl: accessed-variable=VeDHSR_k_FaultLvl.VeDHSR_k_FaultLvl
            OUT_VeDHSR_b_FaultLamp_Rank_CAN_VeDHSR_b_FaultLamp_Rank_CAN: accessed-variable=VeDHSR_b_FaultLamp_Rank_CAN.VeDHSR_b_FaultLamp_Rank_CAN
            OUT_VeDHSR_b_StoredEnergySys_CAN_VeDHSR_b_StoredEnergySys_CAN: accessed-variable=VeDHSR_b_StoredEnergySys_CAN.VeDHSR_b_StoredEnergySys_CAN
            OUT_VeDHSR_k_TempFaultLight_VeDHSR_k_TempFaultLight: accessed-variable=VeDHSR_k_TempFaultLight.VeDHSR_k_TempFaultLight
            OUT_VaDHSR_k_FaultList_CAN_VaDHSR_k_FaultList_CAN: accessed-variable=VaDHSR_k_FaultList_CAN.VaDHSR_k_FaultList_CAN
            OUT_VeDHSR_b_BattPerfomTest_Fault_VeDHSR_b_Ba_4e5d55a44557b37f: accessed-variable=VeDHSR_b_BattPerfomTest_Fault.VeDHSR_b_BattPerfomTest_Fault
            OUT_VeDHSR_k_BMSHardware_flt_VeDHSR_k_BMSHardware_flt: accessed-variable=VeDHSR_k_BMSHardware_flt.VeDHSR_k_BMSHardware_flt
        27 x parameter access:
          CALPRM_DHSR_Rport_KeDHSR_b_BattPowerOff_En: accessed-parameter=DHSR_Rport.KeDHSR_b_BattPowerOff_En
          CALPRM_DHSR_Rport_KeDHSR_b_BattPowerOff_Val: accessed-parameter=DHSR_Rport.KeDHSR_b_BattPowerOff_Val
          CALPRM_DHSR_Rport_KeDHSR_b_ChrgFactor_En: accessed-parameter=DHSR_Rport.KeDHSR_b_ChrgFactor_En
          CALPRM_DHSR_Rport_KeDHSR_b_Discharge10Kw_En: accessed-parameter=DHSR_Rport.KeDHSR_b_Discharge10Kw_En
          CALPRM_DHSR_Rport_KeDHSR_b_Discharge10Kw_Val: accessed-parameter=DHSR_Rport.KeDHSR_b_Discharge10Kw_Val
          CALPRM_DHSR_Rport_KeDHSR_b_FaultLamp_En: accessed-parameter=DHSR_Rport.KeDHSR_b_FaultLamp_En
          CALPRM_DHSR_Rport_KeDHSR_b_FaultLamp_Val: accessed-parameter=DHSR_Rport.KeDHSR_b_FaultLamp_Val
          CALPRM_DHSR_Rport_KeDHSR_b_NoCellBalance_En: accessed-parameter=DHSR_Rport.KeDHSR_b_NoCellBalance_En
          CALPRM_DHSR_Rport_KeDHSR_b_NoCellBalance_Val: accessed-parameter=DHSR_Rport.KeDHSR_b_NoCellBalance_Val
          CALPRM_DHSR_Rport_KeDHSR_b_NoHeat_En: accessed-parameter=DHSR_Rport.KeDHSR_b_NoHeat_En
          CALPRM_DHSR_Rport_KeDHSR_b_NoHeat_Val: accessed-parameter=DHSR_Rport.KeDHSR_b_NoHeat_Val
          CALPRM_DHSR_Rport_KeDHSR_b_NoPrecharge_En: accessed-parameter=DHSR_Rport.KeDHSR_b_NoPrecharge_En
          CALPRM_DHSR_Rport_KeDHSR_b_NoPrecharge_Val: accessed-parameter=DHSR_Rport.KeDHSR_b_NoPrecharge_Val
          CALPRM_DHSR_Rport_KeDHSR_b_RegenFactor_En: accessed-parameter=DHSR_Rport.KeDHSR_b_RegenFactor_En
          CALPRM_DHSR_Rport_KeDHSR_b_ReqPowerOff_En: accessed-parameter=DHSR_Rport.KeDHSR_b_ReqPowerOff_En
          CALPRM_DHSR_Rport_KeDHSR_b_ReqPowerOff_Val: accessed-parameter=DHSR_Rport.KeDHSR_b_ReqPowerOff_Val
          CALPRM_DHSR_Rport_KeDHSR_b_SOCTo0_En: accessed-parameter=DHSR_Rport.KeDHSR_b_SOCTo0_En
          CALPRM_DHSR_Rport_KeDHSR_b_SOCTo0_Val: accessed-parameter=DHSR_Rport.KeDHSR_b_SOCTo0_Val
          CALPRM_DHSR_Rport_KeDHSR_b_SOPFactor_En: accessed-parameter=DHSR_Rport.KeDHSR_b_SOPFactor_En
          CALPRM_DHSR_Rport_KeDHSR_kmh_VehSpeedProgAlwd: accessed-parameter=DHSR_Rport.KeDHSR_kmh_VehSpeedProgAlwd
          CALPRM_DHSR_Rport_KeDHSR_r_ChrgFactor_Val: accessed-parameter=DHSR_Rport.KeDHSR_r_ChrgFactor_Val
          CALPRM_DHSR_Rport_KeDHSR_r_RegenFactor_Val: accessed-parameter=DHSR_Rport.KeDHSR_r_RegenFactor_Val
          CALPRM_DHSR_Rport_KeDHSR_r_SOPFactor_Val: accessed-parameter=DHSR_Rport.KeDHSR_r_SOPFactor_Val
          CALPRM_DHSR_Rport_KeDHSR_t_BPOdbnc{1..4}: accessed-parameter=DHSR_Rport.KeDHSR_t_BPOdbnc{1..4}
